# GBA register map
Vendor: Nintendo; Series: Game Boy; File version: 1.0
Game Boy Advance Hardware Registers
CPU: ARM7TDMI r4p1, little endian, no MPU, no FPU, I-cache, vendor SysTick, 0 interrupt priority bits
Registers are 16-bit, read-write, reset 0x0 unless marked. A register's access mark holds for its fields unless they carry their own. Offsets are from the block's base; lines under a group give offsets from that group; [hi:lo] are bit positions; {n}, {i} and the like mark numbered series; 'fields as' and 'values as' point back to an identical list; <NAME> marks a mode.

## Memory map
0x04000000 LCD_I/O_Registers size 0x64
0x04000060 Sound_Registers size 0x64
0x040000B0 DMA_Transfer_Channels size 0x48
0x04000100 Timer_Registers size 0x1E
0x04000120 Serial_Communication_(1) size 0x20
0x04000130 Keypad_Input size 0x12
0x04000134 Serial_Communication_(2) size 0x40
0x04000200 Interrupt,_Waitstate,_and_Power-Down_Control size 0x109
0x04000410 Undocumented_LCD_Registers size 0x1 — Undocumented LCD-related registers.

## Undocumented_LCD_Registers — Undocumented LCD-related registers.
Base 0x04000410
0x00 OBJ_CENTER 8-bit — Undocumented OBJ window center register.
  [7:0] Center — OBJ window center value.

## Sound_Registers
Base 0x04000060
0x00 SOUND1CNT_L — Channel 1 Sweep register (NR10)
0x02 SOUND1CNT_H — Channel 1 Duty/Length/Envelope (NR11, NR12)
0x04 SOUND1CNT_X — Channel 1 Frequency/Control (NR13, NR14)
0x08 SOUND2CNT_L — Channel 2 Duty/Length/Envelope (NR21, NR22)
0x0C SOUND2CNT_H — Channel 2 Frequency/Control (NR23, NR24)
0x10 SOUND3CNT_L — Channel 3 Stop/Wave RAM select (NR30)
0x12 SOUND3CNT_H — Channel 3 Length/Volume (NR31, NR32)
0x14 SOUND3CNT_X — Channel 3 Frequency/Control (NR33, NR34)
0x18 SOUND4CNT_L — Channel 4 Length/Envelope (NR41, NR42)
0x1C SOUND4CNT_H — Channel 4 Frequency/Control (NR43, NR44)
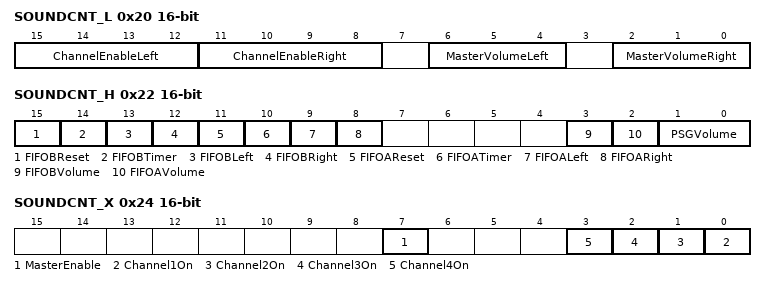
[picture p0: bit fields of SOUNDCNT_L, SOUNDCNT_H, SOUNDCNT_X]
0x20 SOUNDCNT_L — Control Stereo/Volume/Enable (NR50, NR51)
  [15:12] ChannelEnableLeft — Enable flags for PSG channels on the left output.
  [11:8] ChannelEnableRight — Enable flags for PSG channels on the right output.
  [6:4] MasterVolumeLeft — Master volume for PSG channels on the left output.
  [2:0] MasterVolumeRight — Master volume for PSG channels on the right output.
0x22 SOUNDCNT_H — Control Mixing/DMA Control
  [15] FIFOBReset — Reset FIFO B.
  [14] FIFOBTimer — FIFO B timer select: 0=Timer 0, 1=Timer 1.
  [13] FIFOBLeft — Enable FIFO B on the left output.
  [12] FIFOBRight — Enable FIFO B on the right output.
  [11] FIFOAReset — Reset FIFO A.
  [10] FIFOATimer — FIFO A timer select: 0=Timer 0, 1=Timer 1.
  [9] FIFOALeft — Enable FIFO A on the left output.
  [8] FIFOARight — Enable FIFO A on the right output.
  [3] FIFOBVolume — FIFO B volume: 0=50%, 1=100%.
  [2] FIFOAVolume — FIFO A volume: 0=50%, 1=100%.
  [1:0] PSGVolume — PSG channel volume: 0=25%, 1=50%, 2=100%, 3=prohibited.
0x24 SOUNDCNT_X — Control Sound on/off (NR52)
  [7] MasterEnable — Enable PSG and FIFO sound output.
  [n-1] Channel{n}On ro (n=1..4) — Channel {n} active status.
0x40 FIFO_A 32-bit wo — Channel A FIFO, Data 0-3
0x44 FIFO_B 32-bit wo — Channel B FIFO, Data 0-3

## DMA_Transfer_Channels
Base 0x040000B0
0x00 DMA0SAD 32-bit wo — DMA 0 Source Address
  [31:0] DMA0SAD — DMA 0 source address
{0x4+0xC*i} DMA{i}DAD 32-bit wo (i=0..3) — DMA {i} Destination Address
{0x8+0xC*i} DMA{i}CNT_L wo (i=0..3) — DMA {i} Word Count
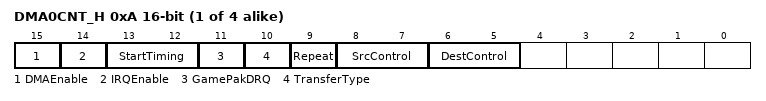
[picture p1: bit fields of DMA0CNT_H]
{0xA+0xC*i} DMA{i}CNT_H (i=0..3) — DMA {i} Control
  [15] DMAEnable — Enable the DMA channel.
  [14] IRQEnable — Generate an interrupt when the transfer completes.
  [13:12] StartTiming — Start timing: 0=immediate, 1=VBlank, 2=HBlank, 3=special.
  [11] GamePakDRQ — Use Game Pak DRQ timing.
  [10] TransferType — Transfer width: 0=16-bit, 1=32-bit.
  [9] Repeat — Repeat the transfer at the selected timing.
  [8:7] SrcControl — Source address adjustment.
  [6:5] DestControl — Destination address adjustment.
{0x0+0xC*i} DMA{i}SAD 32-bit wo (i=1..3) — DMA {i} Source Address
